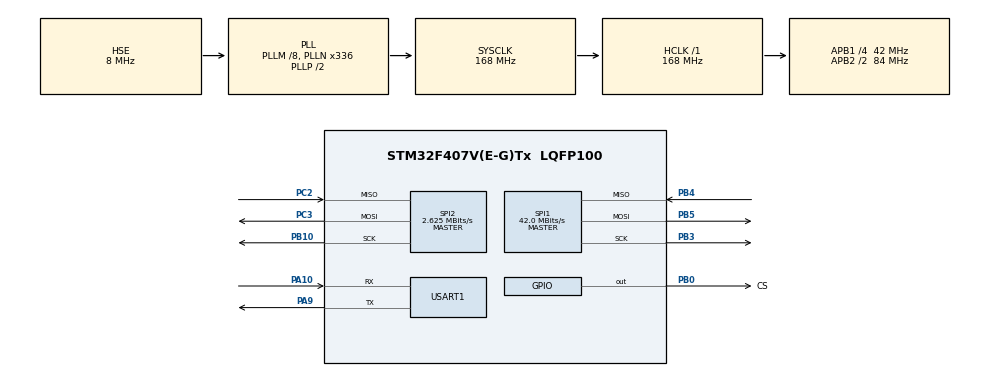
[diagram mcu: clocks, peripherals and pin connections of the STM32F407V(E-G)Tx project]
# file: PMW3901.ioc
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Mcu.Family=STM32F4
Mcu.Name=STM32F407V(E-G)Tx
Mcu.Package=LQFP100
NVIC.PriorityGroup=NVIC_PRIORITYGROUP_4
PA10.Mode=Asynchronous
PA10.Signal=USART1_RX
PA13.Mode=Serial_Wire
PA13.Signal=SYS_JTMS-SWDIO
PA14.Mode=Serial_Wire
PA14.Signal=SYS_JTCK-SWCLK
PA9.Mode=Asynchronous
PA9.Signal=USART1_TX
PB0.GPIO_Label=CS
PB0.Signal=GPIO_Output
PB10.Mode=Full_Duplex_Master
PB10.Signal=SPI2_SCK
PB3.Mode=Full_Duplex_Master
PB3.Signal=SPI1_SCK
PB4.Mode=Full_Duplex_Master
PB4.Signal=SPI1_MISO
PB5.Mode=Full_Duplex_Master
PB5.Signal=SPI1_MOSI
PC2.Mode=Full_Duplex_Master
PC2.Signal=SPI2_MISO
PC3.Mode=Full_Duplex_Master
PC3.Signal=SPI2_MOSI
PH0-OSC_IN.Mode=HSE-External-Oscillator
PH0-OSC_IN.Signal=RCC_OSC_IN
PH1-OSC_OUT.Mode=HSE-External-Oscillator
PH1-OSC_OUT.Signal=RCC_OSC_OUT
ProjectManager.HeapSize=0x200
ProjectManager.StackSize=0x400
ProjectManager.TargetToolchain=STM32CubeIDE
RCC.48MHZClocksFreq_Value=84000000
RCC.AHBFreq_Value=168000000
RCC.APB1CLKDivider=RCC_HCLK_DIV4
RCC.APB1Freq_Value=42000000
RCC.APB1TimFreq_Value=84000000
RCC.APB2CLKDivider=RCC_HCLK_DIV2
RCC.APB2Freq_Value=84000000
RCC.APB2TimFreq_Value=168000000
RCC.CortexFreq_Value=168000000
RCC.HCLKFreq_Value=168000000
RCC.HSE_VALUE=8000000
RCC.HSI_VALUE=16000000
RCC.LSE_VALUE=32768
RCC.PLLM=8
RCC.PLLN=336
RCC.PLLSourceVirtual=RCC_PLLSOURCE_HSE
RCC.SYSCLKFreq_VALUE=168000000
RCC.SYSCLKSource=RCC_SYSCLKSOURCE_PLLCLK
RCC.VCOOutputFreq_Value=336000000
SPI1.CalculateBaudRate=42.0 MBits/s
SPI1.Direction=SPI_DIRECTION_2LINES
SPI1.Mode=SPI_MODE_MASTER
SPI1.VirtualType=VM_MASTER
SPI2.BaudRatePrescaler=SPI_BAUDRATEPRESCALER_16
SPI2.CalculateBaudRate=2.625 MBits/s
SPI2.Direction=SPI_DIRECTION_2LINES
SPI2.Mode=SPI_MODE_MASTER
SPI2.VirtualType=VM_MASTER
USART1.VirtualMode=VM_ASYNC
board=custom

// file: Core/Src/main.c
/* USER CODE BEGIN Header */
/**
  ******************************************************************************
  * @file           : main.c
  * @brief          : Main program body
  ******************************************************************************
  * @attention
  *
  * Copyright (c) 2023 STMicroelectronics.
  * All rights reserved.
  *
  * This software is licensed under terms that can be found in the LICENSE file
  * in the root directory of this software component.
  * If no LICENSE file comes with this software, it is provided AS-IS.
  *
  ******************************************************************************
  */
/* USER CODE END Header */
#include "main.h"
#include "spi.h"
#include "usart.h"
#include "gpio.h"

/* USER CODE BEGIN Includes */
#include "retarget.h"
#include "pmw3901.h"
#include "w25qxx.h"
/* USER CODE END Includes */

/* USER CODE BEGIN PV */
uint8_t RD_Buffer[5000] = {0};
uint8_t WR_Buffer[5000] = "SPI FLASH WRITE TEST\n";
/* USER CODE END PV */

void SystemClock_Config(void);

int main(void)
{
  /* USER CODE BEGIN 1 */
    uint16_t FLASH_ID = 0;
    uint32_t i;
  /* USER CODE END 1 */

  /* MCU Configuration--------------------------------------------------------*/

  /* Reset of all peripherals, Initializes the Flash interface and the Systick. */
  HAL_Init();

  /* Configure the system clock */
  SystemClock_Config();

  /* Initialize all configured peripherals */
  MX_GPIO_Init();
  MX_USART1_UART_Init();
  MX_SPI2_Init();
  MX_SPI1_Init();
  /* USER CODE BEGIN 2 */
  RetargetInit(&huart1);
//    MX_SPI1_Init();

    printf("init uart over\n");
    PMWinit();
    printf("chushihua");
    int16_t deltax, deltay;
    FLASH_ID = sFLASH_ReadID();

    printf("FLASH_ID = %x\n",FLASH_ID);
    /*���Բ���*/
//    sFLASH_EraseSector(4096*0);
//    sFLASH_EraseSector(4096*1);
//    sFLASH_ReadBuffer(RD_Buffer,0,4096);
//    printf("�����ݿ�ʼ\n");
//    for(i=0; i<4096; i++)
//    {
//        printf("%x ",RD_Buffer[i]);
//    }
//    printf("�����ݽ���\n");

//	/*����д����1*/
    //sFLASH_WritePage(WR_Buffer,0, 20);
    //sFLASH_ReadBuffer(RD_Buffer,0,20);
    //printf("READ DATA: %s\n",RD_Buffer);

    /*����д����2*/
//    for(i=0; i<4096; i++)
//    {
//        WR_Buffer[i] = 0x55;
//    }
//    sFLASH_WriteBuffer(WR_Buffer,4090, 1000);
//    sFLASH_ReadBuffer(RD_Buffer,4090,1000);
//    for(i=0; i<1000; i++)
//    {
//        printf("%x ",RD_Buffer[i]);
//    }

  /* USER CODE END 2 */

  /* Infinite loop */
  /* USER CODE BEGIN WHILE */
  while (1)
  {
//      readMotionCount(&deltax, &deltay);
//
//      printf("xx%d ,yy%d\n",deltax,deltay);
//      HAL_Delay(100);
    /* USER CODE END WHILE */

  }
}

void SystemClock_Config(void)
{
  RCC_OscInitTypeDef RCC_OscInitStruct = {0};
  RCC_ClkInitTypeDef RCC_ClkInitStruct = {0};

  /** Configure the main internal regulator output voltage
  */
  __HAL_RCC_PWR_CLK_ENABLE();
  __HAL_PWR_VOLTAGESCALING_CONFIG(PWR_REGULATOR_VOLTAGE_SCALE1);

  /** Initializes the RCC Oscillators according to the specified parameters
  * in the RCC_OscInitTypeDef structure.
  */
  RCC_OscInitStruct.OscillatorType = RCC_OSCILLATORTYPE_HSE;
  RCC_OscInitStruct.HSEState = RCC_HSE_ON;
  RCC_OscInitStruct.PLL.PLLState = RCC_PLL_ON;
  RCC_OscInitStruct.PLL.PLLSource = RCC_PLLSOURCE_HSE;
  RCC_OscInitStruct.PLL.PLLM = 8;
  RCC_OscInitStruct.PLL.PLLN = 336;
  RCC_OscInitStruct.PLL.PLLP = RCC_PLLP_DIV2;
  RCC_OscInitStruct.PLL.PLLQ = 4;
  if (HAL_RCC_OscConfig(&RCC_OscInitStruct) != HAL_OK)
  {
    Error_Handler();
  }

  /** Initializes the CPU, AHB and APB buses clocks
  */
  RCC_ClkInitStruct.ClockType = RCC_CLOCKTYPE_HCLK|RCC_CLOCKTYPE_SYSCLK
                              |RCC_CLOCKTYPE_PCLK1|RCC_CLOCKTYPE_PCLK2;
  RCC_ClkInitStruct.SYSCLKSource = RCC_SYSCLKSOURCE_PLLCLK;
  RCC_ClkInitStruct.AHBCLKDivider = RCC_SYSCLK_DIV1;
  RCC_ClkInitStruct.APB1CLKDivider = RCC_HCLK_DIV4;
  RCC_ClkInitStruct.APB2CLKDivider = RCC_HCLK_DIV2;

  if (HAL_RCC_ClockConfig(&RCC_ClkInitStruct, FLASH_LATENCY_5) != HAL_OK)
  {
    Error_Handler();
  }
}

void Error_Handler(void)
{
  __disable_irq();
  while (1)
  {
  }
}
